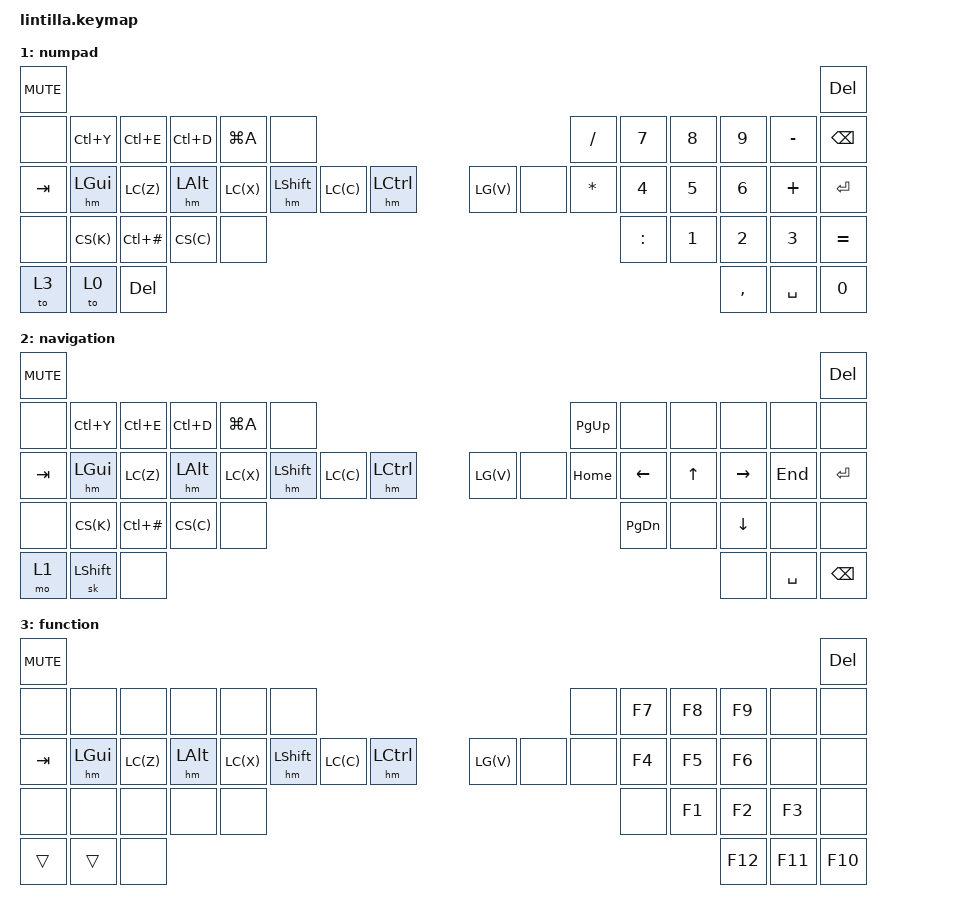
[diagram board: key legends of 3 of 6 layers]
#include <behaviors.dtsi>
#include <dt-bindings/zmk/bt.h>
#include <dt-bindings/zmk/keys.h>
#include <dt-bindings/zmk/outputs.h>
#include <behaviors/rgbled_widget.dtsi>
#include <dt-bindings/zmk/pointing.h>

// Multiple mods
#define CS(key) &kp LC(LS(key))
#define GS(key) &kp LG(LS(key))
#define GCS(key) &kp LG(LC(LS(key)))
#define HYPR(key) &kp LG(LA(LC(LS(key))))

// Shortcuts for home row mods
#define LGm &hm LGUI
#define LAm &hm LALT
#define LSm &hm LSHFT
#define LCm &hm LCTRL

#define RGm &hm RGUI
#define RAm &hm RALT
#define RSm &hm RSHFT
#define RCm &hm RCTRL

// Magic bluetooth button
#define BT_(btnum) &bt_key btnum btnum

/ {
    behaviors {
        hm: homerow_mod {
            compatible = "zmk,behavior-hold-tap";
            #binding-cells = <2>;
            tapping-term-ms = <250>;
            require-prior-idle-ms = <150>;
            quick-tap-ms = <0>;
            flavor = "tap-preferred";
            bindings = <&kp>, <&kp>;
        };

        lt: layer_tap {
            compatible = "zmk,behavior-hold-tap";
            #binding-cells = <2>;
            flavor = "tap-preferred";
            tapping-term-ms = <200>;
            bindings = <&mo>, <&kp>;
            display-name = "Layer-Tap";
        };
    };

    keymap {
        compatible = "zmk,keymap";

        prometheus {
//                       ┏━━━━━━━━━━━━━━━━━━━━━━━━━┓
            display-name = "Prometheus"            ;
//                       ┗━━━━━━━━━━━━━━━━━━━━━━━━━┛
            bindings = <
//         ┏━━━━━━━┓                                                                                          ┏━━━━━━━┓
//           MUTE                                                                                             ┃  DEL  ┃
           &kp C_MUTE                                                                                          &kp DEL
// ┏━━━━━━━╋━━━━━━━╋━━━━━━━┳━━━━━━━┳━━━━━━━┳━━━━━━━┓                          ┏━━━━━━━┳━━━━━━━┳━━━━━━━┳━━━━━━━╋━━━━━━━╋━━━━━━━┓
// ┃  ESC  ┃   F   ┃   P   ┃   D   ┃   L   ┃   X   ┃                          ┃   ;   ┃   U   ┃   O   ┃   Y   ┃   B   ┃   Z   ┃
    &kp ESC  &kp F   &kp P   &kp D   &kp L   &kp X                            &kp SEMI  &kp U   &kp O   &kp Y   &kp B   &kp Z
// ┣━━━━━━━╋━━━━━━━╋━━━━━━━╋━━━━━━━╋━━━━━━━╋━━━━━━━┫                          ┣━━━━━━━╋━━━━━━━╋━━━━━━━╋━━━━━━━╋━━━━━━━╋━━━━━━━┫
// ┃  TAB  ┃   S   ┃   N   ┃   T   ┃   H   ┃   K   ┃                          ┃   ,   ┃   A   ┃   E   ┃   I   ┃   C   ┃   Q   ┃
   &lt 4 DEL LGm S   LAm N   LSm T   LCm H   &kp K                           &kp COMMA  RCm A   RSm K   RAm L   RGm C   &kp Q
// ┃ keybd ┃  GUI  ┃  ALT  ┃  SHFT ┃  CTRL ┃       ┃                          ┃       ┃  CTRL ┃  SHFT ┃  ALT  ┃  GUI  ┃       ┃
// ┗━━━━━━━╋━━━━━━━╋━━━━━━━╋━━━━━━━╋━━━━━━━╋━━━━━━━┫                          ┣━━━━━━━╋━━━━━━━╋━━━━━━━╋━━━━━━━╋━━━━━━━╋━━━━━━━┛
//         ┃   V   ┃   W   ┃   G   ┃   M   ┃   J   ┃                          ┃   -   ┃   .   ┃   '   ┃   =   ┃   /   ┃
             &kp V   &kp W   &kp G   &kp M   &kp J                          &kp MINUS &kp DOT &kp SQT &kp EQUAL &kp SLASH
//         ┗━━━━━━━┻━━━━━━━┻━━━━━━━┻━━━┳━━━┻━━━┳━━━┻━━━┳━━━━━━━┓  ┏━━━━━━━┳━━━┻━━━┳━━━┻━━━┳━━━┻━━━━━━━┻━━━━━━━┻━━━━━━━┛
//                                     ┃   R   ┃ SHIFT ┃  DEL  ┃  ┃  L1   ┃ SPACE ┃ BKSPC ┃
                                       &kp R  &sk LSHIFT &kp DEL     &to 1  &kp SPC &kp BSPC
//                                     ┗━━━━━━━┫       ┣━━━━━━━┛  ┗━━━━━━━┫       ┣━━━━━━━┛
//                                             ┗━━━━━━━┛                  ┗━━━━━━━┛
            >;
        };
   
        num {
//                       ┏━━━━━━━━━━━━━━━━━━━━━━━━━┓
            display-name = "numpad"                ;
//                       ┗━━━━━━━━━━━━━━━━━━━━━━━━━┛
            bindings = <
//         ┏━━━━━━━┓                                                                                          ┏━━━━━━━┓
//           MUTE                                                                                             ┃  DEL  ┃
           &kp C_MUTE                                                                                          &kp DEL
// ┏━━━━━━━╋━━━━━━━╋━━━━━━━┳━━━━━━━┳━━━━━━━┳━━━━━━━┓                          ┏━━━━━━━┳━━━━━━━┳━━━━━━━┳━━━━━━━╋━━━━━━━╋━━━━━━━┓
// ┃       ┃ CtrlY ┃ CtrlE ┃ CtrlD ┃ CtrlA ┃       ┃                          ┃   /   ┃   7   ┃   8   ┃   9   ┃   -   ┃ BKSPC ┃
  &none &kp LC(Y) &kp LC(E) &kp LC(D) &kp LG(A) &none                            &kp SLASH &kp N7 &kp N8  &kp N9 &kp MINUS &kp BSPC
// ┣━━━━━━━╋━━━━━━━╋━━━━━━━╋━━━━━━━╋━━━━━━━╋━━━━━━━┫                          ┣━━━━━━━╋━━━━━━━╋━━━━━━━╋━━━━━━━╋━━━━━━━╋━━━━━━━┫
// ┃       ┃ CtrlZ ┃ CtrlX ┃ CtrlC ┃ CtrlV ┃       ┃                          ┃   *   ┃   4   ┃   5   ┃   6   ┃   +   ┃RETURN ┃
&kp TAB LGm LC(Z) LAm LC(X) LSm LC(C) LCm LG(V) &none                            &kp STAR &kp N4  &kp N5  &kp N6 &kp PLUS &kp RET
// ┃       ┃  GUI  ┃  ALT  ┃  SHFT ┃  CTRL ┃       ┃                          ┃       ┃       ┃       ┃       ┃       ┃       ┃
// ┗━━━━━━━╋━━━━━━━╋━━━━━━━╋━━━━━━━╋━━━━━━━╋━━━━━━━┫                          ┣━━━━━━━╋━━━━━━━╋━━━━━━━╋━━━━━━━╋━━━━━━━╋━━━━━━━┛
//         ┃       ┃ CS-K  ┃ CS-C  ┃ CS-C  ┃       ┃                          ┃   :   ┃   1   ┃   2   ┃   3   ┃   =   ┃
             &none  CS(K) &kp LC(HASH) CS(C) &none                            &kp COLON &kp N1 &kp N2  &kp N3 &kp EQUAL
//         ┗━━━━━━━┻━━━━━━━┻━━━━━━━┻━━━┳━━━┻━━━┳━━━┻━━━┳━━━━━━━┓  ┏━━━━━━━┳━━━┻━━━┳━━━┻━━━┳━━━┻━━━━━━━┻━━━━━━━┻━━━━━━━┛
//                                     ┃   L3  ┃   L0  ┃  DEL  ┃  ┃   .   ┃ SPACE ┃   0   ┃
                                         &to 3   &to 0   &kp DEL  &kp COMMA &kp SPC &kp N0
//                                     ┗━━━━━━━┫       ┣━━━━━━━┛  ┗━━━━━━━┫       ┣━━━━━━━┛
//                                             ┗━━━━━━━┛                  ┗━━━━━━━┛
            >;
        };

        nav {
//                       ┏━━━━━━━━━━━━━━━━━━━━━━━━━┓
            display-name = "navigation"            ;
//                       ┗━━━━━━━━━━━━━━━━━━━━━━━━━┛
            bindings = <
//         ┏━━━━━━━┓                                                                                          ┏━━━━━━━┓
//           MUTE                                                                                             ┃  DEL  ┃
           &kp C_MUTE                                                                                          &kp DEL
// ┏━━━━━━━╋━━━━━━━╋━━━━━━━┳━━━━━━━┳━━━━━━━┳━━━━━━━┓                          ┏━━━━━━━┳━━━━━━━┳━━━━━━━┳━━━━━━━╋━━━━━━━╋━━━━━━━┓
// ┃       ┃ CtrlY ┃ CtrlE ┃ CtrlD ┃ CtrlA ┃       ┃                          ┃ Pg Up ┃       ┃       ┃       ┃       ┃      ┃
  &none &kp LC(Y) &kp LC(E) &kp LC(D) &kp LG(A) &none                         &kp PG_UP &none   &none   &none   &none  &none
// ┣━━━━━━━╋━━━━━━━╋━━━━━━━╋━━━━━━━╋━━━━━━━╋━━━━━━━┫                          ┣━━━━━━━╋━━━━━━━╋━━━━━━━╋━━━━━━━╋━━━━━━━╋━━━━━━━┫
// ┃       ┃ CtrlZ ┃ CtrlX ┃ CtrlC ┃ CtrlV ┃       ┃                          ┃ Home  ┃ Left  ┃  Up   ┃ Right ┃  End  ┃RETURN ┃
&kp TAB LGm LC(Z) LAm LC(X) LSm LC(C) LCm LG(V) &none                      &kp HOME &kp LEFT &kp UP &kp RIGHT &kp END &kp RET
// ┃       ┃  GUI  ┃  ALT  ┃  SHFT ┃  CTRL ┃       ┃                          ┃       ┃       ┃       ┃       ┃       ┃       ┃
// ┗━━━━━━━╋━━━━━━━╋━━━━━━━╋━━━━━━━╋━━━━━━━╋━━━━━━━┫                          ┣━━━━━━━╋━━━━━━━╋━━━━━━━╋━━━━━━━╋━━━━━━━╋━━━━━━━┛
//         ┃       ┃ CS-K  ┃ CS-C  ┃ CS-C  ┃       ┃                          ┃ Pg Dn ┃       ┃ Down  ┃       ┃       ┃
             &none  CS(K) &kp LC(HASH) CS(C) &none                            &kp PG_DN &none  &kp DOWN &none   &none
//         ┗━━━━━━━┻━━━━━━━┻━━━━━━━┻━━━┳━━━┻━━━┳━━━┻━━━┳━━━━━━━┓  ┏━━━━━━━┳━━━┻━━━┳━━━┻━━━┳━━━┻━━━━━━━┻━━━━━━━┻━━━━━━━┛
//                                     ┃  fn   ┃       ┃       ┃  ┃       ┃ SPACE ┃ BKSPC ┃
                                         &mo 1 &sk LSHFT &none      &none  &kp SPC &kp BSPC
//                                     ┗━━━━━━━┫       ┣━━━━━━━┛  ┗━━━━━━━┫       ┣━━━━━━━┛
//                                             ┗━━━━━━━┛                  ┗━━━━━━━┛
            >;
        };

        fn {
//                       ┏━━━━━━━━━━━━━━━━━━━━━━━━━┓
            display-name = "function"              ;
//                       ┗━━━━━━━━━━━━━━━━━━━━━━━━━┛
            bindings = <
//         ┏━━━━━━━┓                                                                                          ┏━━━━━━━┓
//           MUTE                                                                                             ┃  DEL  ┃
           &kp C_MUTE                                                                                          &kp DEL
// ┏━━━━━━━╋━━━━━━━╋━━━━━━━┳━━━━━━━┳━━━━━━━┳━━━━━━━┓                          ┏━━━━━━━┳━━━━━━━┳━━━━━━━┳━━━━━━━╋━━━━━━━╋━━━━━━━┓
// ┃       ┃       ┃       ┃       ┃       ┃       ┃                          ┃       ┃  F7   ┃  F8   ┃  F9   ┃       ┃       ┃
     &none   &none   &none   &none   &none   &none                              &none  &kp F7  &kp F8  &kp F9   &none   &none
// ┣━━━━━━━╋━━━━━━━╋━━━━━━━╋━━━━━━━╋━━━━━━━╋━━━━━━━┫                          ┣━━━━━━━╋━━━━━━━╋━━━━━━━╋━━━━━━━╋━━━━━━━╋━━━━━━━┫
// ┃       ┃ CtrlZ ┃ CtrlX ┃ CtrlC ┃ CtrlV ┃       ┃                          ┃       ┃  F4   ┃  F5   ┃  F6   ┃       ┃       ┃
&kp TAB LGm LC(Z) LAm LC(X) LSm LC(C) LCm LG(V) &none                           &none  &kp F4  &kp F5  &kp F6   &none   &none
// ┗━━━━━━━╋━━━━━━━╋━━━━━━━╋━━━━━━━╋━━━━━━━╋━━━━━━━┫                          ┣━━━━━━━╋━━━━━━━╋━━━━━━━╋━━━━━━━╋━━━━━━━╋━━━━━━━┛
//         ┃       ┃       ┃       ┃       ┃       ┃                          ┃       ┃  F1   ┃  F2   ┃  F3   ┃       ┃
             &none   &none   &none   &none   &none                              &none  &kp F1  &kp F2  &kp F3   &none
//         ┗━━━━━━━┻━━━━━━━┻━━━━━━━┻━━━┳━━━┻━━━┳━━━┻━━━┳━━━━━━━┓  ┏━━━━━━━┳━━━┻━━━┳━━━┻━━━┳━━━┻━━━━━━━┻━━━━━━━┻━━━━━━━┛
//                                     ┃ ##### ┃ ##### ┃       ┃  ┃  F12  ┃  F11  ┃  F10  ┃
                                         &trans  &trans  &none     &kp F12 &kp F11 &kp F10
//                                     ┗━━━━━━━┫       ┣━━━━━━━┛  ┗━━━━━━━┫       ┣━━━━━━━┛
//                                             ┗━━━━━━━┛                  ┗━━━━━━━┛
            >;
        };

        keybd {
//                       ┏━━━━━━━━━━━━━━━━━━━━━━━━━┓
            display-name = "keyboard"              ;
//                       ┗━━━━━━━━━━━━━━━━━━━━━━━━━┛
            bindings = <
//         ┏━━━━━━━┓                                                                                          ┏━━━━━━━┓
//           MUTE                                                                                             ┃  DEL  ┃
           &kp C_MUTE                                                                                          &kp DEL
// ┏━━━━━━━╋━━━━━━━╋━━━━━━━┳━━━━━━━┳━━━━━━━┳━━━━━━━┓                          ┏━━━━━━━┳━━━━━━━┳━━━━━━━┳━━━━━━━╋━━━━━━━╋━━━━━━━┓
// ┃ dongle┃       ┃       ┃       ┃       ┃       ┃                          ┃con led┃       ┃bat led┃       ┃       ┃       ┃
  &bootloader   &none   &none  &none   &none    &none                            &ind_con  &none &ind_bat  &none   &none   &none
// ┣━━━━━━━╋━━━━━━━╋━━━━━━━╋━━━━━━━╋━━━━━━━╋━━━━━━━┫                          ┣━━━━━━━╋━━━━━━━╋━━━━━━━╋━━━━━━━╋━━━━━━━╋━━━━━━━┫
// ┃ ##### ┃       ┃scrnsht┃       ┃       ┃       ┃                          ┃       ┃       ┃       ┃       ┃       ┃       ┃
    &trans   &none   GS(S)   &none   &none   &none                              &none   &none   &none   &none   &none   &none
// ┗━━━━━━━╋━━━━━━━╋━━━━━━━╋━━━━━━━╋━━━━━━━╋━━━━━━━┫                          ┣━━━━━━━╋━━━━━━━╋━━━━━━━╋━━━━━━━╋━━━━━━━╋━━━━━━━┛
//         ┃       ┃       ┃caps lk┃ numlk ┃       ┃                          ┃       ┃       ┃       ┃       ┃       ┃
            &none   &none &kp CAPS &kp LNLCK &none                              &none   &none   &none   &none   &none
//         ┗━━━━━━━┻━━━━━━━┻━━━━━━━┻━━━┳━━━┻━━━┳━━━┻━━━┳━━━━━━━┓  ┏━━━━━━━┳━━━┻━━━┳━━━┻━━━┳━━━┻━━━━━━━┻━━━━━━━┻━━━━━━━┛
//                                     ┃ vol - ┃ mute  ┃ vol + ┃  ┃ prev  ┃ play  ┃ next  ┃
                             &kp C_VOL_DN &kp C_MUTE &kp C_VOL_UP &kp C_PREV &kp C_PP &kp C_NEXT
//                                     ┗━━━━━━━┫       ┣━━━━━━━┛  ┗━━━━━━━┫       ┣━━━━━━━┛
//                                             ┗━━━━━━━┛                  ┗━━━━━━━┛
            >;
        };
        
        sym {
//                       ┏━━━━━━━━━━━━━━━━━━━━━━━━━┓
            display-name = "symbols"               ;
//                       ┗━━━━━━━━━━━━━━━━━━━━━━━━━┛
            bindings = <
//         ┏━━━━━━━┓                                                                                          ┏━━━━━━━┓
//           MUTE                                                                                             ┃  DEL  ┃
           &kp C_MUTE                                                                                          &kp DEL
// ┏━━━━━━━╋━━━━━━━╋━━━━━━━┳━━━━━━━┳━━━━━━━┳━━━━━━━┓                          ┏━━━━━━━┳━━━━━━━┳━━━━━━━┳━━━━━━━╋━━━━━━━╋━━━━━━━┓
// ┃   ~   ┃   !   ┃   @   ┃   #   ┃   $   ┃   %   ┃                          ┃   ^   ┃   &   ┃   *   ┃   (   ┃   )   ┃   \   ┃
&kp TILDE &kp EXCL &kp AT &kp HASH &kp DLLR &kp PRCNT                      &kp CARET &kp AMPS &kp STAR &kp LPAR &kp RPAR &kp BSLH
// ┣━━━━━━━╋━━━━━━━╋━━━━━━━╋━━━━━━━╋━━━━━━━╋━━━━━━━┫                          ┣━━━━━━━╋━━━━━━━╋━━━━━━━╋━━━━━━━╋━━━━━━━╋━━━━━━━┫
// ┃   `   ┃ LGUI  ┃ LALT  ┃ LCTRL ┃ LSHFT ┃       ┃                          ┃   [   ┃   ]   ┃   -   ┃   =   ┃       ┃   |   ┃
&kp GRAVE     LGm     LAm     LSm     LCm   &none                            &kp LBKT &kp RBKT &kp MINUS &kp EQUAL &none &kp PIPE
// ┗━━━━━━━╋━━━━━━━╋━━━━━━━╋━━━━━━━╋━━━━━━━╋━━━━━━━┫                          ┣━━━━━━━╋━━━━━━━╋━━━━━━━╋━━━━━━━╋━━━━━━━╋━━━━━━━┛
//         ┃ CtrlZ ┃ CtrlX ┃ CtrlC ┃ CtrlV ┃       ┃                          ┃   <   ┃   >   ┃   _   ┃   +   ┃       ┃
       &kp LC(Z) &kp LC(X) &kp LC(C) &kp LC(V) &none                           &kp LT &kp GT &kp UNDER &kp PLUS &none
//         ┗━━━━━━━┻━━━━━━━┻━━━━━━━┻━━━┳━━━┻━━━┳━━━┻━━━┳━━━━━━━┓  ┏━━━━━━━┳━━━┻━━━┳━━━┻━━━┳━━━┻━━━━━━━┻━━━━━━━┻━━━━━━━┛
//                                     ┃       ┃ LSHFT ┃       ┃  ┃ ##### ┃       ┃       ┃
                                         &none &kp LSHFT &none      &trans  &none  &none
//                                     ┗━━━━━━━┫       ┣━━━━━━━┛  ┗━━━━━━━┫       ┣━━━━━━━┛
//                                             ┗━━━━━━━┛                  ┗━━━━━━━┛
            >;
        };
    };
};

// vim: expandtab softtabstop=4 shiftwidth=4 filetype=dts
